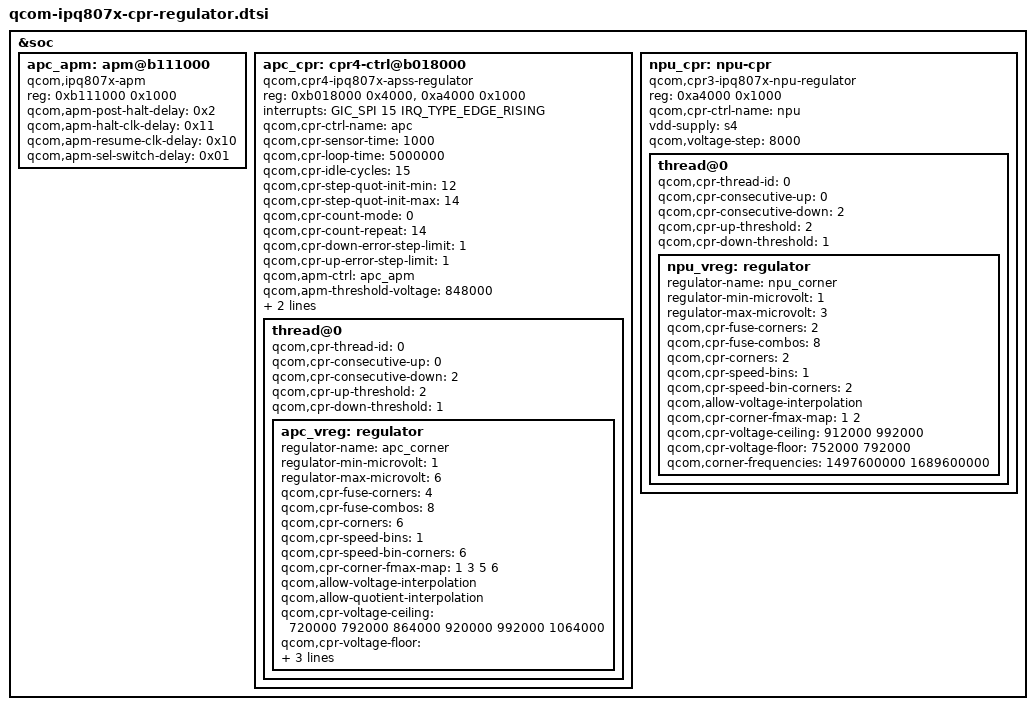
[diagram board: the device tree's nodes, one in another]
/*
 * Copyright (c) 2017, The Linux Foundation. All rights reserved.
 *
 * Permission to use, copy, modify, and/or distribute this software for any
 * purpose with or without fee is hereby granted, provided that the above
 * copyright notice and this permission notice appear in all copies.
 *
 * THE SOFTWARE IS PROVIDED "AS IS" AND THE AUTHOR DISCLAIMS ALL WARRANTIES
 * WITH REGARD TO THIS SOFTWARE INCLUDING ALL IMPLIED WARRANTIES OF
 * MERCHANTABILITY AND FITNESS. IN NO EVENT SHALL THE AUTHOR BE LIABLE FOR
 * ANY SPECIAL, DIRECT, INDIRECT, OR CONSEQUENTIAL DAMAGES OR ANY DAMAGES
 * WHATSOEVER RESULTING FROM LOSS OF USE, DATA OR PROFITS, WHETHER IN AN
 * ACTION OF CONTRACT, NEGLIGENCE OR OTHER TORTIOUS ACTION, ARISING OUT OF
 * OR IN CONNECTION WITH THE USE OR PERFORMANCE OF THIS SOFTWARE.
 */

#include "qcom-ipq807x-spmi-regulator.dtsi"

&soc {
	apc_apm: apm@b111000 {
		compatible = "qcom,ipq807x-apm";
		reg = <0xb111000 0x1000>;
		reg-names = "pm-apcc-glb";
		qcom,apm-post-halt-delay = <0x2>;
		qcom,apm-halt-clk-delay = <0x11>;
		qcom,apm-resume-clk-delay = <0x10>;
		qcom,apm-sel-switch-delay = <0x01>;
	};

	apc_cpr: cpr4-ctrl@b018000 {
		compatible = "qcom,cpr4-ipq807x-apss-regulator";
		reg = <0xb018000 0x4000>, <0xa4000 0x1000>;
		reg-names = "cpr_ctrl", "fuse_base";
		interrupts = <GIC_SPI 15 IRQ_TYPE_EDGE_RISING>;
		interrupt-names = "cpr";
		qcom,cpr-ctrl-name = "apc";
		qcom,cpr-sensor-time = <1000>;
		qcom,cpr-loop-time = <5000000>;
		qcom,cpr-idle-cycles = <15>;
		qcom,cpr-step-quot-init-min = <12>;
		qcom,cpr-step-quot-init-max = <14>;
		qcom,cpr-count-mode = <0>;		/* All-at-once */
		qcom,cpr-count-repeat = <14>;
		qcom,cpr-down-error-step-limit = <1>;
		qcom,cpr-up-error-step-limit = <1>;
		qcom,apm-ctrl = <&apc_apm>;
		qcom,apm-threshold-voltage = <848000>;
		vdd-supply = <&s3>;
		qcom,voltage-step = <8000>;

		thread@0 {
			qcom,cpr-thread-id = <0>;
			qcom,cpr-consecutive-up = <0>;
			qcom,cpr-consecutive-down = <2>;
			qcom,cpr-up-threshold = <2>;
			qcom,cpr-down-threshold = <1>;

			apc_vreg: regulator {
				regulator-name = "apc_corner";
				regulator-min-microvolt = <1>;
				regulator-max-microvolt = <6>;
				qcom,cpr-fuse-corners = <4>;
				qcom,cpr-fuse-combos = <8>;
				qcom,cpr-corners = <6>;
				qcom,cpr-speed-bins = <1>;
				qcom,cpr-speed-bin-corners = <6>;
				qcom,cpr-corner-fmax-map = <1 3 5 6>;
				qcom,allow-voltage-interpolation;
				qcom,allow-quotient-interpolation;
				qcom,cpr-voltage-ceiling =
					<720000 792000 864000
					 920000 992000 1064000>;
				qcom,cpr-voltage-floor =
					<592000 648000 712000
					 744000 784000 848000>;
				qcom,corner-frequencies =
					<1017600000 1382400000 1651200000
					1843200000 1920000000 2208000000>;
			};
		};
	};

	npu_cpr: npu-cpr {
		compatible = "qcom,cpr3-ipq807x-npu-regulator";
		reg = <0xa4000 0x1000>;
		reg-names = "fuse_base";
		qcom,cpr-ctrl-name = "npu";
		vdd-supply = <&s4>;
		qcom,voltage-step = <8000>;
		thread@0 {
			qcom,cpr-thread-id = <0>;
			qcom,cpr-consecutive-up = <0>;
			qcom,cpr-consecutive-down = <2>;
			qcom,cpr-up-threshold = <2>;
			qcom,cpr-down-threshold = <1>;

			npu_vreg: regulator {
				regulator-name = "npu_corner";
				regulator-min-microvolt = <1>;
				regulator-max-microvolt = <3>;
				qcom,cpr-fuse-corners = <2>;
				qcom,cpr-fuse-combos = <8>;
				qcom,cpr-corners = <2>;
				qcom,cpr-speed-bins = <1>;
				qcom,cpr-speed-bin-corners = <2>;
				qcom,allow-voltage-interpolation;
				qcom,cpr-corner-fmax-map = <1 2>;
				qcom,cpr-voltage-ceiling =
					<912000 992000>;
				qcom,cpr-voltage-floor =
					<752000 792000>;
				qcom,corner-frequencies =
					<1497600000 1689600000>;
			};
		};
	};
};
